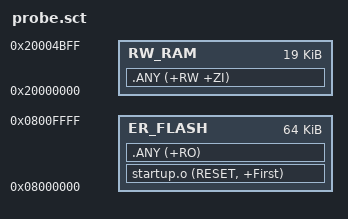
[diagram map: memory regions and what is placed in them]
; 保留 STM32F103C8 标称 64 KiB Flash / 20 KiB RAM 边界，不使用扩容假设。
; 向量表必须置于加载区首部，栈固定于 RAM 顶端，不包含 C 库初始化。
LR_FLASH 0x08000000 0x10000 {
  ER_FLASH 0x08000000 0x10000 {
    startup.o (RESET, +First)
    .ANY (+RO)
  }
  RW_RAM 0x20000000 0x4C00 {
    .ANY (+RW +ZI)
  }
}
